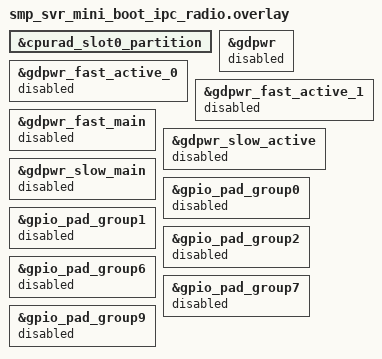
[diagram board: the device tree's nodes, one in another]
/*
 * Copyright (c) 2025 Nordic Semiconductor ASA
 *
 * SPDX-License-Identifier: LicenseRef-Nordic-5-Clause
 */

#include "nrf54h20.overlay"

/* The zephyr,code-partition is always set to fw_loader_partition in firmware
 * loader image(s).
 */
/delete-node/ &slot1_partition;
slot1_partition: &cpurad_slot0_partition {};

&gdpwr {
	status = "disabled";
};

&gdpwr_fast_active_0 {
	status = "disabled";
};

&gdpwr_fast_active_1 {
	status = "disabled";
};

&gdpwr_fast_main {
	status = "disabled";
};

&gdpwr_slow_active {
	status = "disabled";
};

&gdpwr_slow_main {
	status = "disabled";
};

&gpio_pad_group0 {
	status = "disabled";
};

&gpio_pad_group1 {
	status = "disabled";
};

&gpio_pad_group2 {
	status = "disabled";
};

&gpio_pad_group6 {
	status = "disabled";
};

&gpio_pad_group7 {
	status = "disabled";
};

&gpio_pad_group9 {
	status = "disabled";
};
